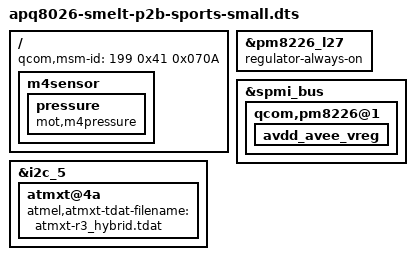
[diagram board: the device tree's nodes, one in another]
/* Copyright (c) 2015, The Linux Foundation. All rights reserved.
 *
 * This program is free software; you can redistribute it and/or modify
 * it under the terms of the GNU General Public License version 2 and
 * only version 2 as published by the Free Software Foundation.
 *
 * This program is distributed in the hope that it will be useful,
 * but WITHOUT ANY WARRANTY; without even the implied warranty of
 * MERCHANTABILITY or FITNESS FOR A PARTICULAR PURPOSE.  See the
 * GNU General Public License for more details.
 */

/dts-v1/;

#include "apq8026-smelt-common.dtsi"
#include "apq8026-smelt-sports-small-tsl2584-config.dtsi"
#include "apq8026-smelt-panel-nt35355-small.dtsi"
#include "apq8026-smelt-regulator-ote2005b.dtsi"
#include "apq8026-smelt-gps.dtsi"

/ {
	qcom,msm-id =
		<199 0x41 0x070A>; /* Sports Small P2B Portable */

	m4sensor {
		pressure {
			compatible = "mot,m4pressure";
		};
	};
};

&i2c_5 {
	atmxt@4a {
		atmel,atmxt-tdat-filename = "atmxt-r3_hybrid.tdat";
	};
};

&pm8226_l27 {
	regulator-always-on;
};

&spmi_bus {
	qcom,pm8226@1 {
		avdd_avee_vreg: avdd_avee_vreg {
			/delete-property/ mot,pull-down-delay;
		};
	};
};
